# STM8L101G3 register map
Vendor: STMicroelectronics; Series: STM8L101, low density; File version: 1.0
CPU: other r1p0, big endian, no MPU, no FPU, 4 interrupt priority bits
Registers are 8-bit, read-write, reset 0x0 unless marked. A register's access mark holds for its fields unless they carry their own. Offsets are from the block's base; [hi:lo] are bit positions; {n}, {i} and the like mark numbered series.

## FLASH
Base 0x00005050
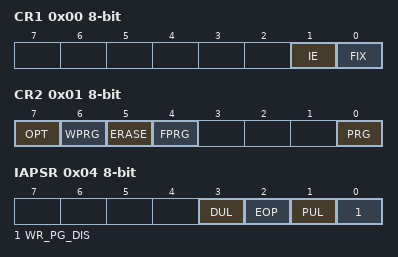
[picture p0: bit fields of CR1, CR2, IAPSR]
0x00 CR1 — Flash control register 1
  [1] IE, [0] FIX
0x01 CR2 — Flash control register 2
  [7] OPT, [6] WPRG, [5] ERASE, [4] FPRG, [0] PRG
0x02 PUKR — Flash Program memory unprotection register
  [7:0] MASS_PRG
0x03 DUKR — Data EEPROM unprotection register
  [7:0] MASS_DATA
0x04 IAPSR — Flash in-application programming status register
  [3] DUL, [2] EOP, [1] PUL, [0] WR_PG_DIS

## I2C
Base 0x00005210
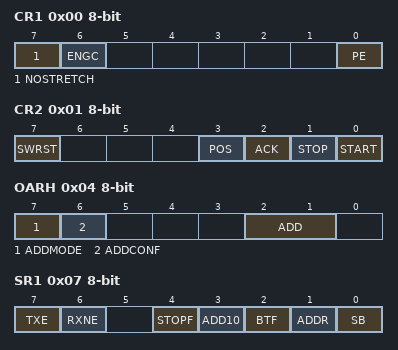
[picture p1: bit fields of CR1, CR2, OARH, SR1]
0x00 CR1 — I2C control register 1
  [7] NOSTRETCH, [6] ENGC, [0] PE
0x01 CR2 — I2C control register 2
  [7] SWRST, [3] POS, [2] ACK, [1] STOP, [0] START
0x02 FREQR — I2C frequency register
  [5:0] FREQ
0x03 OARL — I2C Own address register low
  [7:0] ADD
0x04 OARH — I2C Own address register high
  [7] ADDMODE, [6] ADDCONF, [2:1] ADD
0x06 DR — I2C data register
0x07 SR1 — I2C status register 1
  [7] TXE, [6] RXNE, [4] STOPF, [3] ADD10, [2] BTF, [1] ADDR, [0] SB
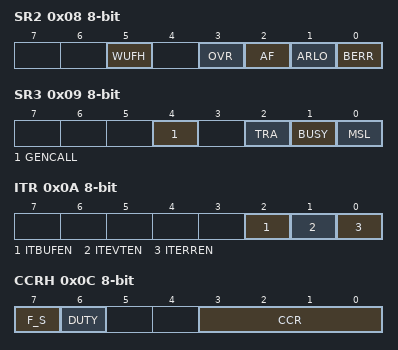
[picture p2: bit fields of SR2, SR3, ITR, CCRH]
0x08 SR2 — I2C status register 2
  [5] WUFH, [3] OVR, [2] AF, [1] ARLO, [0] BERR
0x09 SR3 — I2C status register 3
  [4] GENCALL, [2] TRA, [1] BUSY, [0] MSL
0x0A ITR — I2C interrupt control register
  [2] ITBUFEN, [1] ITEVTEN, [0] ITERREN
0x0B CCRL — I2C Clock control register low
  [7:0] CCR
0x0C CCRH — I2C Clock control register high
  [7] F_S, [6] DUTY, [3:0] CCR
0x0D TRISER reset 0x2 — I2C TRISE register
  [5:0] TRISE

## IR
Base 0x000052FF
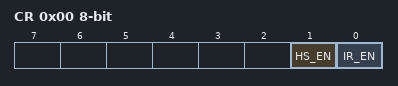
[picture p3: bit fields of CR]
0x00 CR — Infra-red control register
  [1] HS_EN, [0] IR_EN

## ITC_EXTI
Base 0x000050A0
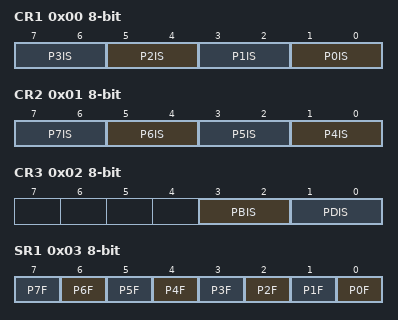
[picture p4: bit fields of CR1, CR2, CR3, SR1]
0x00 CR1 — External interrupt control register 1
  [2n+1:2n] P{n}IS (n=0..3)
0x01 CR2 — External interrupt control register 2
  [2n-7:2n-8] P{n}IS (n=4..7)
0x02 CR3 — External interrupt control register 3
  [3:2] PBIS, [1:0] PDIS
0x03 SR1 — External interrupt status register 1
  [n] P{n}F (n=0..7)
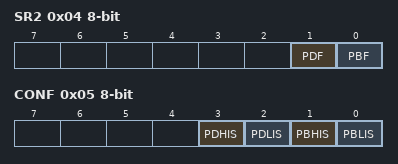
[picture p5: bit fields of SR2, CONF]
0x04 SR2 — External interrupt status register 2
  [1] PDF, [0] PBF
0x05 CONF — External interrupt port select register
  [3] PDHIS, [2] PDLIS, [1] PBHIS, [0] PBLIS

## ITC_SPR
Base 0x00007F70
0x00 SPR1 reset 0xFF — Interrupt Software priority register 1
  [3:2] VECT1SPR
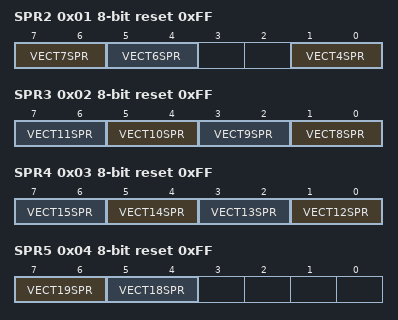
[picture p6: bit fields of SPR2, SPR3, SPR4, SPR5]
0x01 SPR2 reset 0xFF — Interrupt Software priority register 2
  [7:6] VECT7SPR, [5:4] VECT6SPR, [1:0] VECT4SPR
0x02 SPR3 reset 0xFF — Interrupt Software priority register 3
  [2n-15:2n-16] VECT{n}SPR (n=8..11)
0x03 SPR4 reset 0xFF — Interrupt Software priority register 4
  [2n-23:2n-24] VECT{n}SPR (n=12..15)
0x04 SPR5 reset 0xFF — Interrupt Software priority register 5
  [7:6] VECT19SPR, [5:4] VECT18SPR
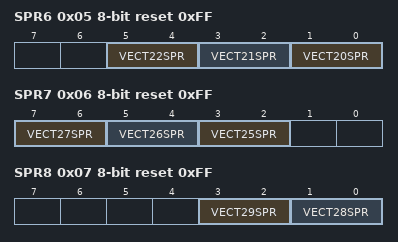
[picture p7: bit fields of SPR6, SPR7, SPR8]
0x05 SPR6 reset 0xFF — Interrupt Software priority register 6
  [5:4] VECT22SPR, [3:2] VECT21SPR, [1:0] VECT20SPR
0x06 SPR7 reset 0xFF — Interrupt Software priority register 7
  [7:6] VECT27SPR, [5:4] VECT26SPR, [3:2] VECT25SPR
0x07 SPR8 reset 0xFF — Interrupt Software priority register 8
  [3:2] VECT29SPR, [1:0] VECT28SPR

## IWDG
Base 0x000050E0
0x00 KR — IWDG Key register
  [7:0] KEY
0x01 PR — IWDG Prescaler register
  [2:0] PR
0x02 RLR reset 0xFF — IWDG Reload register
  [7:0] RL

## OPT
Base 0x00004800
0x00 OPT1 — Read-out protection (ROP)
0x02 OPT2 — UBC (User Boot code size)
0x03 OPT3 — DATASIZE
0x08 OPT4 — Independent watchdog option

## PORTA
Base 0x00005000
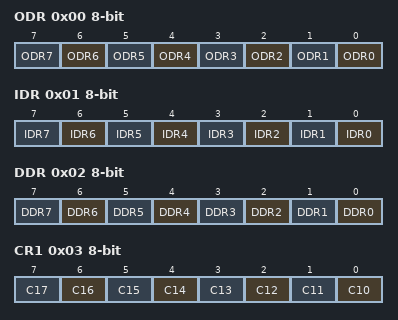
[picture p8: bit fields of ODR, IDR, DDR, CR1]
0x00 ODR — Port A data output latch register
  [n] ODR{n} (n=0..7)
0x01 IDR — Port A input pin value register
  [n] IDR{n} (n=0..7)
0x02 DDR — Port A data direction register
  [n] DDR{n} (n=0..7)
0x03 CR1 — Port A control register 1
  [n-10] C{n} (n=10..17)
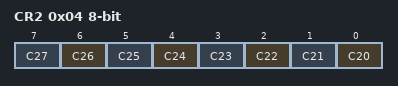
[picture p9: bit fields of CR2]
0x04 CR2 — Port A control register 2
  [n-20] C{n} (n=20..27)

## PORTB
Base 0x00005005
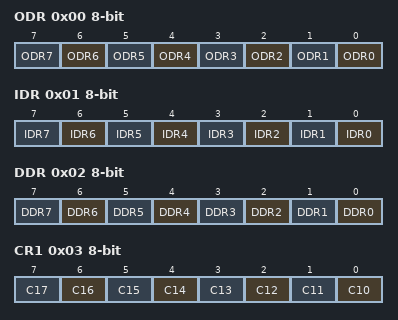
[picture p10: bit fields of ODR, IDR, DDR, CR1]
0x00 ODR — Port B data output latch register
  [n] ODR{n} (n=0..7)
0x01 IDR — Port B input pin value register
  [n] IDR{n} (n=0..7)
0x02 DDR — Port B data direction register
  [n] DDR{n} (n=0..7)
0x03 CR1 — Port B control register 1
  [n-10] C{n} (n=10..17)
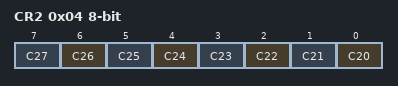
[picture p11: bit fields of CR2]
0x04 CR2 — Port B control register 2
  [n-20] C{n} (n=20..27)
